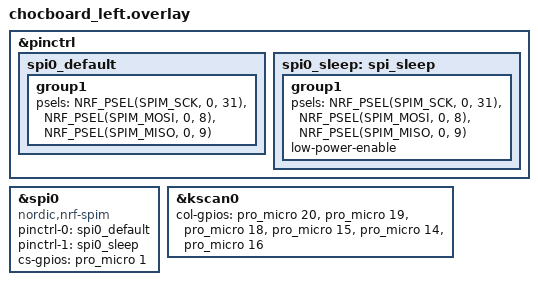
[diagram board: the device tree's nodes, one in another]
#include "chocboard.dtsi" // Notice that the main dtsi files are included in the overlay.
//nice_view_spi: &spi0 {
//	compatible = "nordic,nrf-spim";
//	sck-pin = <31>;
//	mosi-pin = <8>;
//    miso-pin = <9>;
//	cs-gpios = <&pro_micro 1 GPIO_ACTIVE_HIGH>;
//};

&pinctrl {
	spi0_default: spi0_default {
		group1 {
			psels = <NRF_PSEL(SPIM_SCK, 0, 31)>,
				<NRF_PSEL(SPIM_MOSI, 0, 8)>,
				<NRF_PSEL(SPIM_MISO, 0, 9)>;
		};
	};
    spi0_sleep: spi_sleep {
        group1 {
            psels = <NRF_PSEL(SPIM_SCK, 0, 31)>,
                <NRF_PSEL(SPIM_MOSI, 0, 8)>,
                <NRF_PSEL(SPIM_MISO, 0, 9)>;
            low-power-enable;
        };
    };
};

nice_view_spi: &spi0 {
    compatible = "nordic,nrf-spim";
    status = "okay";
    pinctrl-0 = <&spi0_default>;
    pinctrl-1 = <&spi0_sleep>;
    pinctrl-names = "default", "sleep";
    cs-gpios = <&pro_micro 1 GPIO_ACTIVE_HIGH>;
};

&kscan0 {
    col-gpios
        = <&pro_micro 20 GPIO_ACTIVE_HIGH> // col1 in the schematic
        , <&pro_micro 19 GPIO_ACTIVE_HIGH> // col2 in the schematic
        , <&pro_micro 18 GPIO_ACTIVE_HIGH> // col3 in the schematic
        , <&pro_micro 15 GPIO_ACTIVE_HIGH> // col4 in the schematic
        , <&pro_micro 14 GPIO_ACTIVE_HIGH> // col5 in the schematic
        , <&pro_micro 16 GPIO_ACTIVE_HIGH> // col6 in the schematic
        ;
};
